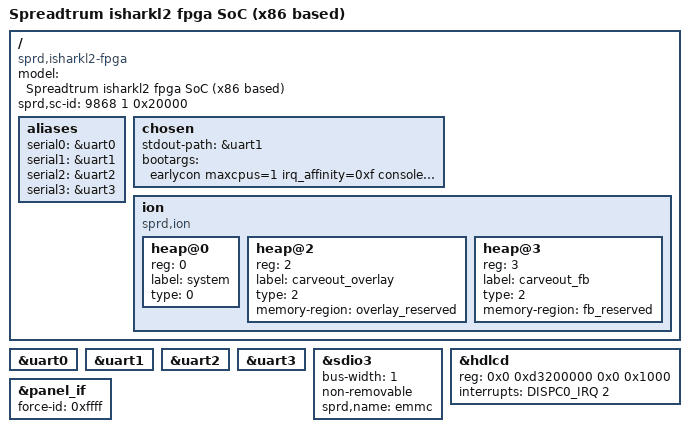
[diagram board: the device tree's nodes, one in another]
/*
 * Spreadtrum isharkl2 fpga board DTS file
 *
 * Copyright (C) 2016, Spreadtrum Communications Inc.
 *
 * This file is licensed under a dual GPLv2 or X11 license.
 */

/dts-v1/;

#include "sp9853i-presi-common.dtsi"
#include "sp9853i-memory.dtsi"

/ {
	model = "Spreadtrum isharkl2 fpga SoC (x86 based)";

	compatible = "sprd,isharkl2-fpga";

	sprd,sc-id = <9868 1 0x20000>;

	aliases {
		serial0 = &uart0;
		serial1 = &uart1;
		serial2 = &uart2;
		serial3 = &uart3;
	};

	chosen {
		stdout-path = &uart1;
		bootargs = "earlycon maxcpus=1 irq_affinity=0xf console=ttyS1,115200n8 androidboot.hardware=sp9853i loglevel=11";
	};

	ion {
		compatible = "sprd,ion";
		#address-cells = <1>;
		#size-cells = <0>;

		heap@0 {
			reg = <0>;
			label = "system";
			type = <0>;
		};

		heap@2 {
			reg = <2>;
			label = "carveout_overlay";
			type = <2>;
			memory-region = <&overlay_reserved>;
		};

		heap@3 {
			reg = <3>;
			label = "carveout_fb";
			type = <2>;
			memory-region = <&fb_reserved>;
		};
	};


};


&uart0 {
	status = "okay";
};

&uart1 {
	status = "okay";
};

&uart2 {
	status = "okay";
};

&uart3 {
	status = "okay";
};

&sdio3 {
	bus-width = <1>;
	non-removable;
	sprd,name = "emmc";
	status = "okay";
};

&hdlcd {
	reg = <0x0 0xd3200000 0x0 0x1000>; /* use dispc0 */
	interrupts = <DISPC0_IRQ 2>; /* use dispc0 */
};

&panel_if {
	force-id=<0xffff>;
};
